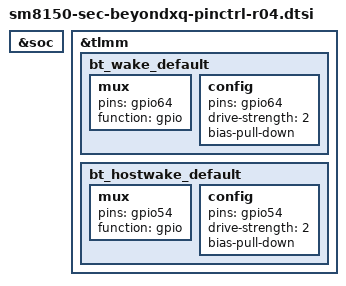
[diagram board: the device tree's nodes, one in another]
/* Copyright (c) 2016-2017, The Linux Foundation. All rights reserved.
 *
 * This program is free software; you can redistribute it and/or modify
 * it under the terms of the GNU General Public License version 2 and
 * only version 2 as published by the Free Software Foundation.
 *
 * This program is distributed in the hope that it will be useful,
 * but WITHOUT ANY WARRANTY; without even the implied warranty of
 * MERCHANTABILITY or FITNESS FOR A PARTICULAR PURPOSE.  See the
 * GNU General Public License for more details.
 */

#include "sm8150-sec-beyondxq-pinctrl-common.dtsi"
#include "../../../../../drivers/motor/tuning/beyondxq_motor_tuning.dtsi"

&soc {
	/* tlmm: pinctrl@03400000 { }; */
};
&tlmm {
	bt_wake_default: bt_wake_default {
		mux {
			pins = "gpio64";
			function = "gpio";
		};
		config {
			pins = "gpio64";
			drive-strength = <2>;
			bias-pull-down;
		};
	};
	bt_hostwake_default: bt_hostwake_default {
		mux {
			pins = "gpio54";
			function = "gpio";
		};
		config {
			pins = "gpio54";
			drive-strength = <2>;
			bias-pull-down;
		};
	};
};
